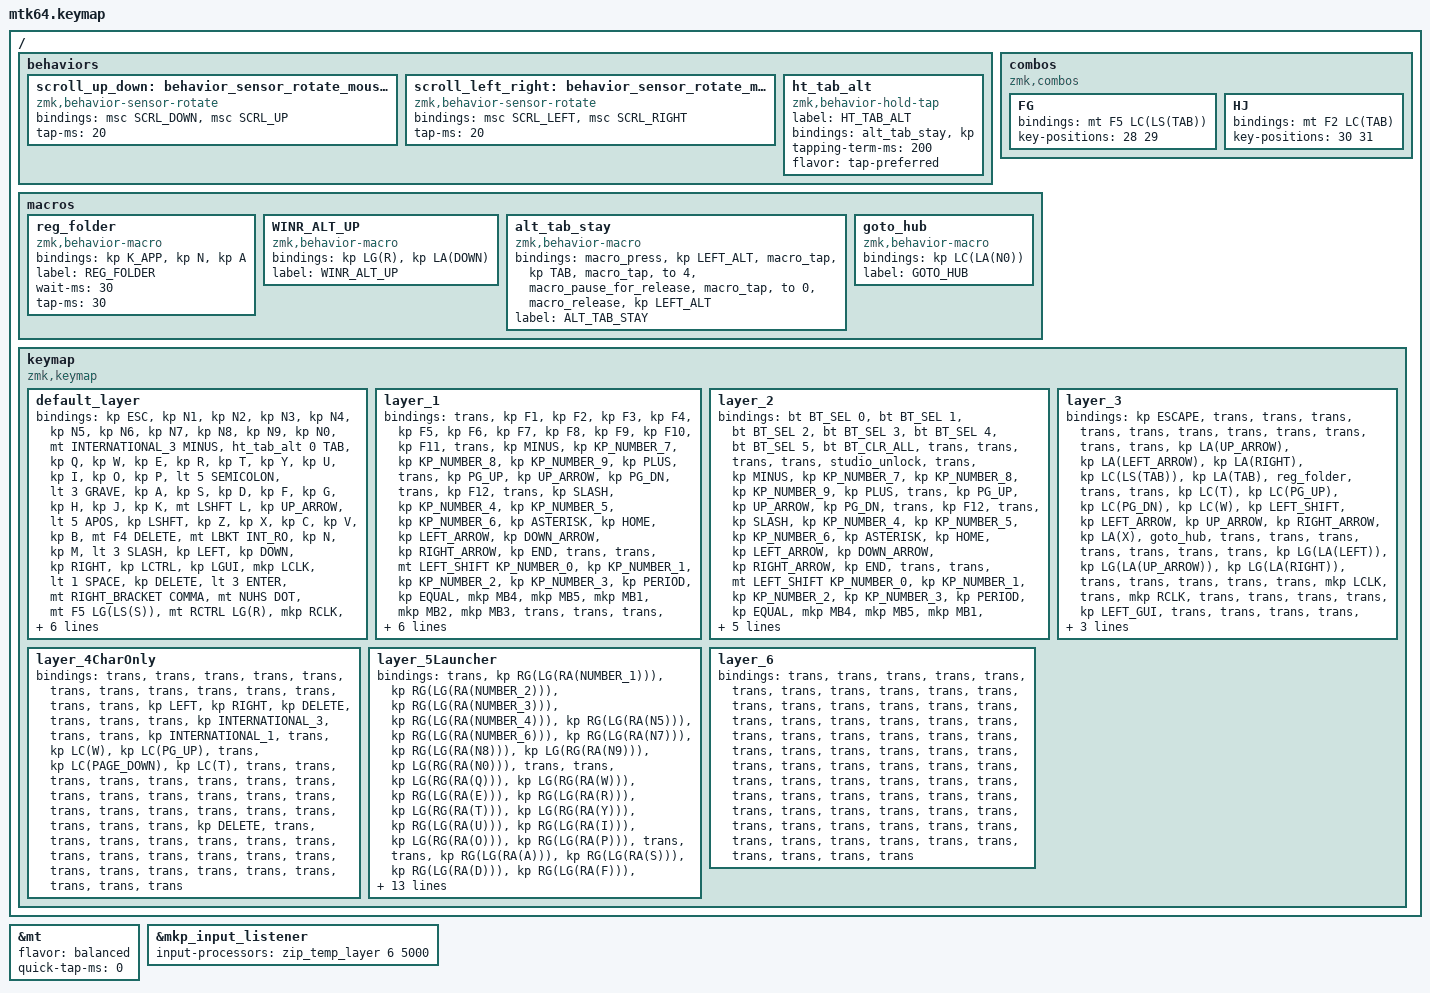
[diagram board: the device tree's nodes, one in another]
#include <input/processors.dtsi>
#include <behaviors.dtsi>
#include <dt-bindings/zmk/bt.h>
#include <dt-bindings/zmk/keys.h>
#include <dt-bindings/zmk/pointing.h>
#include "keycode_japanese.h"

// スクロール量の設定

#define ZMK_POINTING_DEFAULT_SCRL_VAL 100

&mt {
    flavor = "balanced";
    quick-tap-ms = <0>;
};

&mkp_input_listener { input-processors = <&zip_temp_layer 6 5000>; };

/ {
    behaviors {
        // 垂直スクロール用のbehaviorの設定

        scroll_up_down: behavior_sensor_rotate_mouse_wheel_up_down {
            compatible = "zmk,behavior-sensor-rotate";
            #sensor-binding-cells = <0>;
            bindings = <&msc SCRL_DOWN>, <&msc SCRL_UP>;

            tap-ms = <20>; // スクロールのタップ時間
        };

        // 水平スクロール用のbehaviorの設定

        scroll_left_right: behavior_sensor_rotate_mouse_wheel_left_right {
            compatible = "zmk,behavior-sensor-rotate";
            #sensor-binding-cells = <0>;
            bindings = <&msc SCRL_LEFT>, <&msc SCRL_RIGHT>;

            tap-ms = <20>; // スクロールのタップ時間
        };

        ht_tab_alt: ht_tab_alt {
            compatible = "zmk,behavior-hold-tap";
            label = "HT_TAB_ALT";
            bindings = <&alt_tab_stay>, <&kp>;

            #binding-cells = <2>;
            tapping-term-ms = <200>;
            flavor = "tap-preferred";
        };
    };
};

/ {
    combos {
        compatible = "zmk,combos";

        FG {
            bindings = <&mt F5 LC(LS(TAB))>;
            key-positions = <28 29>;
        };

        HJ {
            bindings = <&mt F2 LC(TAB)>;
            key-positions = <30 31>;
        };
    };

    macros {
        reg_folder: reg_folder {
            compatible = "zmk,behavior-macro";
            #binding-cells = <0>;
            bindings = <&kp K_APP &kp N &kp A>;
            label = "REG_FOLDER";
            wait-ms = <30>;
            tap-ms = <30>;
        };

        WINR_ALT_UP: WINR_ALT_UP {
            compatible = "zmk,behavior-macro";
            #binding-cells = <0>;
            bindings = <&kp LG(R) &kp LA(DOWN)>;
            label = "WINR_ALT_UP";
        };

        alt_tab_stay: alt_tab_stay {
            compatible = "zmk,behavior-macro";
            #binding-cells = <0>;
            bindings =
                <&macro_press>,
                <&kp LEFT_ALT>,
                <&macro_tap>,
                <&kp TAB>,
                <&macro_tap>,
                <&to 4>,
                <&macro_pause_for_release>,
                <&macro_tap>,
                <&to 0>,
                <&macro_release>,
                <&kp LEFT_ALT>;

            label = "ALT_TAB_STAY";
        };

        goto_hub: goto_hub {
            compatible = "zmk,behavior-macro";
            #binding-cells = <0>;
            bindings = <&kp LC(LA(N0))>;
            label = "GOTO_HUB";
        };
    };

    keymap {
        compatible = "zmk,keymap";

        default_layer {
            bindings = <
&kp ESC  &kp N1  &kp N2  &kp N3  &kp N4  &kp N5  &kp N6  &kp N7  &kp N8  &kp N9  &kp N0  &mt INTERNATIONAL_3 MINUS  &ht_tab_alt 0 TAB  &kp Q  &kp W  &kp E  &kp R  &kp T  &kp Y  &kp U  &kp I  &kp O  &kp P  &lt 5 SEMICOLON  &lt 3 GRAVE  &kp A  &kp S  &kp D  &kp F  &kp G  &kp H  &kp J  &kp K  &mt LSHFT L  &kp UP_ARROW  &lt 5 APOS  &kp LSHFT  &kp Z  &kp X  &kp C  &kp V  &kp B  &mt F4 DELETE  &mt LBKT INT_RO  &kp N  &kp M  &lt 3 SLASH  &kp LEFT  &kp DOWN  &kp RIGHT  &kp LCTRL  &kp LGUI  &mkp LCLK  &lt 1 SPACE  &kp DELETE  &lt 3 ENTER  &mt RIGHT_BRACKET COMMA  &mt NUHS DOT  &mt F5 LG(LS(S))  &mt RCTRL LG(R)  &mkp RCLK  &kp RCTRL  &kp ENTER  &tog 1  &kp LEFT_ALT  &kp BACKSPACE  &mo 2  &mo 1  &mo 3  &mo 2  &mo 1  &mo 3  &mo 2  &mo 1  &mo 3
            >;

            sensor-bindings =
                <&inc_dec_kp C_VOLUME_DOWN C_VOLUME_UP>,
                <&inc_dec_kp LC(LS(TAB)) LC(TAB)>;
        };

        layer_1 {
            bindings = <
&trans  &kp F1  &kp F2  &kp F3  &kp F4  &kp F5  &kp F6  &kp F7  &kp F8  &kp F9  &kp F10  &kp F11  &trans  &kp MINUS  &kp KP_NUMBER_7  &kp KP_NUMBER_8  &kp KP_NUMBER_9  &kp PLUS  &trans  &kp PG_UP  &kp UP_ARROW  &kp PG_DN  &trans  &kp F12  &trans  &kp SLASH  &kp KP_NUMBER_4  &kp KP_NUMBER_5  &kp KP_NUMBER_6  &kp ASTERISK  &kp HOME  &kp LEFT_ARROW  &kp DOWN_ARROW  &kp RIGHT_ARROW  &kp END  &trans  &trans  &mt LEFT_SHIFT KP_NUMBER_0  &kp KP_NUMBER_1  &kp KP_NUMBER_2  &kp KP_NUMBER_3  &kp PERIOD  &kp EQUAL  &mkp MB4  &mkp MB5  &mkp MB1  &mkp MB2  &mkp MB3  &trans  &trans  &trans  &trans  &trans  &trans  &trans  &trans  &trans  &trans  &trans  &trans  &trans  &trans  &trans  &trans  &trans  &trans  &trans  &trans  &trans  &trans  &trans  &trans  &trans  &trans  &trans
            >;

            sensor-bindings = <
                &inc_dec_kp TAB LC(TAB) 
                &inc_dec_kp PG_UP PG_DN
            >;
        };

        layer_2 {
            bindings = <
&bt BT_SEL 0  &bt BT_SEL 1  &bt BT_SEL 2  &bt BT_SEL 3  &bt BT_SEL 4  &bt BT_SEL 5  &bt BT_CLR_ALL  &trans  &trans  &trans  &trans  &studio_unlock  &trans  &kp MINUS  &kp KP_NUMBER_7  &kp KP_NUMBER_8  &kp KP_NUMBER_9  &kp PLUS  &trans  &kp PG_UP  &kp UP_ARROW  &kp PG_DN  &trans  &kp F12  &trans  &kp SLASH  &kp KP_NUMBER_4  &kp KP_NUMBER_5  &kp KP_NUMBER_6  &kp ASTERISK  &kp HOME  &kp LEFT_ARROW  &kp DOWN_ARROW  &kp RIGHT_ARROW  &kp END  &trans  &trans  &mt LEFT_SHIFT KP_NUMBER_0  &kp KP_NUMBER_1  &kp KP_NUMBER_2  &kp KP_NUMBER_3  &kp PERIOD  &kp EQUAL  &mkp MB4  &mkp MB5  &mkp MB1  &mkp MB2  &mkp MB3  &trans  &trans  &trans  &trans  &trans  &trans  &trans  &trans  &trans  &trans  &trans  &trans  &trans  &trans  &trans  &trans  &trans  &trans  &trans  &trans  &trans  &trans  &trans  &trans  &trans  &trans  &trans
            >;
        };

        layer_3 {
            bindings = <
&kp ESCAPE  &trans  &trans  &trans  &trans  &trans  &trans  &trans  &trans  &trans  &trans  &trans  &kp LA(UP_ARROW)  &kp LA(LEFT_ARROW)  &kp LA(RIGHT)  &kp LC(LS(TAB))  &kp LA(TAB)  &reg_folder  &trans  &trans  &kp LC(T)  &kp LC(PG_UP)  &kp LC(PG_DN)  &kp LC(W)  &kp LEFT_SHIFT  &kp LEFT_ARROW  &kp UP_ARROW  &kp RIGHT_ARROW  &kp LA(X)  &goto_hub  &trans  &trans  &trans  &trans  &trans  &trans  &trans  &kp LG(LA(LEFT))  &kp LG(LA(UP_ARROW))  &kp LG(LA(RIGHT))  &trans  &trans  &trans  &trans  &trans  &mkp LCLK  &trans  &mkp RCLK  &trans  &trans  &trans  &trans  &kp LEFT_GUI  &trans  &trans  &trans  &trans  &trans
            >;

            sensor-bindings =
                <&scroll_left_right>,
                <&inc_dec_kp LC(TAB) LC(LS(TAB))>;
        };

        layer_4CharOnly {
            bindings = <
&trans  &trans  &trans  &trans  &trans  &trans  &trans  &trans  &trans  &trans  &trans  &trans  &trans  &kp LEFT  &kp RIGHT  &kp DELETE  &trans  &trans  &trans  &kp INTERNATIONAL_3  &trans  &trans  &kp INTERNATIONAL_1  &trans  &kp LC(W)  &kp LC(PG_UP)  &trans  &kp LC(PAGE_DOWN)  &kp LC(T)  &trans  &trans  &trans  &trans  &trans  &trans  &trans  &trans  &trans  &trans  &trans  &trans  &trans  &trans  &trans  &trans  &trans  &trans  &trans  &trans  &trans  &trans  &trans  &kp DELETE  &trans  &trans  &trans  &trans  &trans  &trans  &trans  &trans  &trans  &trans  &trans  &trans  &trans  &trans  &trans  &trans  &trans  &trans  &trans  &trans  &trans  &trans
            >;
        };

        layer_5Launcher {
            bindings = <
&trans  &kp RG(LG(RA(NUMBER_1)))  &kp RG(LG(RA(NUMBER_2)))  &kp RG(LG(RA(NUMBER_3)))  &kp RG(LG(RA(NUMBER_4)))  &kp RG(LG(RA(N5)))  &kp RG(LG(RA(NUMBER_6)))  &kp RG(LG(RA(N7)))  &kp RG(LG(RA(N8)))  &kp LG(RG(RA(N9)))  &kp LG(RG(RA(N0)))  &trans  &trans  &kp LG(RG(RA(Q)))  &kp LG(RG(RA(W)))  &kp RG(LG(RA(E)))  &kp RG(LG(RA(R)))  &kp LG(RG(RA(T)))  &kp LG(RG(RA(Y)))  &kp RG(LG(RA(U)))  &kp RG(LG(RA(I)))  &kp LG(RG(RA(O)))  &kp RG(LG(RA(P)))  &trans  &trans  &kp RG(LG(RA(A)))  &kp RG(LG(RA(S)))  &kp RG(LG(RA(D)))  &kp RG(LG(RA(F)))  &kp RG(LG(RA(G)))  &kp RG(LG(RA(H)))  &kp RG(LG(RA(H)))  &kp LG(RG(RA(K)))  &kp RG(LG(RA(L)))  &trans  &trans  &trans  &kp LG(RG(RA(Z)))  &kp LG(RG(RA(X)))  &kp RG(LG(RA(C)))  &kp RG(LG(RA(V)))  &kp RG(LG(RA(B)))  &trans  &trans  &kp RG(LG(RA(N)))  &kp RG(LG(RA(M)))  &kp RG(LG(RA(SLASH)))  &trans  &trans  &trans  &trans  &trans  &trans  &trans  &trans  &trans  &trans  &trans  &trans  &trans  &trans  &trans  &trans  &trans  &trans  &trans  &trans  &trans  &trans  &trans  &trans  &trans  &trans  &trans  &trans
            >;
        };

        layer_6 {
            bindings = <
&trans  &trans  &trans  &trans  &trans  &trans  &trans  &trans  &trans  &trans  &trans  &trans  &trans  &trans  &trans  &trans  &trans  &trans  &trans  &trans  &trans  &trans  &trans  &trans  &trans  &trans  &trans  &trans  &trans  &trans  &trans  &trans  &trans  &trans  &trans  &trans  &trans  &trans  &trans  &trans  &trans  &trans  &trans  &trans  &trans  &trans  &trans  &trans  &trans  &trans  &trans  &trans  &trans  &trans  &trans  &trans  &trans  &trans  &trans  &trans  &trans  &trans  &trans  &trans  &trans  &trans  &trans  &trans  &trans  &trans  &trans  &trans  &trans  &trans  &trans
            >;
        };
    };
};
